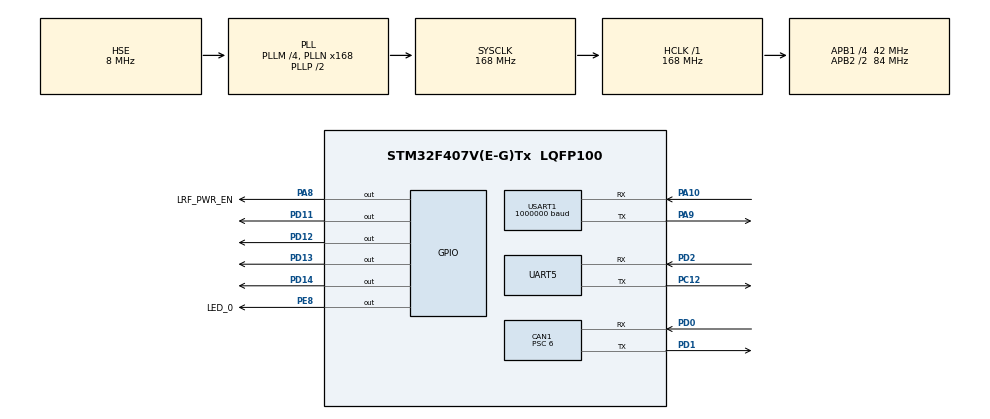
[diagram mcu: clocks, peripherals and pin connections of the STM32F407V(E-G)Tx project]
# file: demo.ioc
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CAN1.BS1=CAN_BS1_11TQ
CAN1.BS2=CAN_BS2_2TQ
CAN1.CalculateBaudRate=500000
CAN1.CalculateTimeBit=2000
CAN1.CalculateTimeQuantum=142.85714285714286
CAN1.Prescaler=6
Dma.Request0=UART5_RX
Dma.Request1=UART5_TX
Dma.Request2=USART1_RX
Dma.Request3=USART1_TX
Dma.UART5_RX.0.Direction=DMA_PERIPH_TO_MEMORY
Dma.UART5_RX.0.FIFOMode=DMA_FIFOMODE_DISABLE
Dma.UART5_RX.0.Instance=DMA1_Stream0
Dma.UART5_RX.0.MemDataAlignment=DMA_MDATAALIGN_BYTE
Dma.UART5_RX.0.MemInc=DMA_MINC_ENABLE
Dma.UART5_RX.0.Mode=DMA_NORMAL
Dma.UART5_RX.0.PeriphDataAlignment=DMA_PDATAALIGN_BYTE
Dma.UART5_RX.0.PeriphInc=DMA_PINC_DISABLE
Dma.UART5_RX.0.Priority=DMA_PRIORITY_LOW
Dma.UART5_TX.1.Direction=DMA_MEMORY_TO_PERIPH
Dma.UART5_TX.1.FIFOMode=DMA_FIFOMODE_DISABLE
Dma.UART5_TX.1.Instance=DMA1_Stream7
Dma.UART5_TX.1.MemDataAlignment=DMA_MDATAALIGN_BYTE
Dma.UART5_TX.1.MemInc=DMA_MINC_ENABLE
Dma.UART5_TX.1.Mode=DMA_NORMAL
Dma.UART5_TX.1.PeriphDataAlignment=DMA_PDATAALIGN_BYTE
Dma.UART5_TX.1.PeriphInc=DMA_PINC_DISABLE
Dma.UART5_TX.1.Priority=DMA_PRIORITY_LOW
Dma.USART1_RX.2.Direction=DMA_PERIPH_TO_MEMORY
Dma.USART1_RX.2.FIFOMode=DMA_FIFOMODE_DISABLE
Dma.USART1_RX.2.Instance=DMA2_Stream2
Dma.USART1_RX.2.MemDataAlignment=DMA_MDATAALIGN_BYTE
Dma.USART1_RX.2.MemInc=DMA_MINC_ENABLE
Dma.USART1_RX.2.Mode=DMA_NORMAL
Dma.USART1_RX.2.PeriphDataAlignment=DMA_PDATAALIGN_BYTE
Dma.USART1_RX.2.PeriphInc=DMA_PINC_DISABLE
Dma.USART1_RX.2.Priority=DMA_PRIORITY_LOW
Dma.USART1_TX.3.Direction=DMA_MEMORY_TO_PERIPH
Dma.USART1_TX.3.FIFOMode=DMA_FIFOMODE_DISABLE
Dma.USART1_TX.3.Instance=DMA2_Stream7
Dma.USART1_TX.3.MemDataAlignment=DMA_MDATAALIGN_BYTE
Dma.USART1_TX.3.MemInc=DMA_MINC_ENABLE
Dma.USART1_TX.3.Mode=DMA_NORMAL
Dma.USART1_TX.3.PeriphDataAlignment=DMA_PDATAALIGN_BYTE
Dma.USART1_TX.3.PeriphInc=DMA_PINC_DISABLE
Dma.USART1_TX.3.Priority=DMA_PRIORITY_LOW
Mcu.Family=STM32F4
Mcu.Name=STM32F407V(E-G)Tx
Mcu.Package=LQFP100
NVIC.DMA1_Stream0_IRQn=true\:0\:0\:false\:false\:true\:false\:true\:true
NVIC.DMA1_Stream7_IRQn=true\:0\:0\:false\:false\:true\:false\:true\:true
NVIC.DMA2_Stream2_IRQn=true\:0\:0\:false\:false\:true\:false\:true\:true
NVIC.DMA2_Stream7_IRQn=true\:0\:0\:false\:false\:true\:false\:true\:true
NVIC.PriorityGroup=NVIC_PRIORITYGROUP_4
NVIC.UART5_IRQn=true\:0\:0\:false\:false\:true\:true\:true\:true
PA10.Mode=Asynchronous
PA10.Signal=USART1_RX
PA13.Mode=Serial_Wire
PA13.Signal=SYS_JTMS-SWDIO
PA14.Mode=Serial_Wire
PA14.Signal=SYS_JTCK-SWCLK
PA8.GPIO_Label=LRF_PWR_EN
PA8.GPIO_PuPd=GPIO_NOPULL
PA8.PinState=GPIO_PIN_SET
PA8.Signal=GPIO_Output
PA9.Mode=Asynchronous
PA9.Signal=USART1_TX
PC12.Mode=Asynchronous
PC12.Signal=UART5_TX
PC14-OSC32_IN.Mode=LSE-External-Oscillator
PC14-OSC32_IN.Signal=RCC_OSC32_IN
PC15-OSC32_OUT.Mode=LSE-External-Oscillator
PC15-OSC32_OUT.Signal=RCC_OSC32_OUT
PD0.Mode=CAN_Activate
PD0.Signal=CAN1_RX
PD1.Mode=CAN_Activate
PD1.Signal=CAN1_TX
PD11.GPIO_Speed=GPIO_SPEED_FREQ_VERY_HIGH
PD11.Signal=GPIO_Output
PD12.GPIO_Speed=GPIO_SPEED_FREQ_VERY_HIGH
PD12.Signal=GPIO_Output
PD13.GPIO_Speed=GPIO_SPEED_FREQ_VERY_HIGH
PD13.Signal=GPIO_Output
PD14.GPIO_Speed=GPIO_SPEED_FREQ_VERY_HIGH
PD14.Signal=GPIO_Output
PD2.Mode=Asynchronous
PD2.Signal=UART5_RX
PE8.GPIO_Label=LED_0
PE8.Signal=GPIO_Output
PH0-OSC_IN.Mode=HSE-External-Oscillator
PH0-OSC_IN.Signal=RCC_OSC_IN
PH1-OSC_OUT.Mode=HSE-External-Oscillator
PH1-OSC_OUT.Signal=RCC_OSC_OUT
ProjectManager.HeapSize=0x200
ProjectManager.StackSize=0x400
ProjectManager.TargetToolchain=Makefile
RCC.48MHZClocksFreq_Value=84000000
RCC.AHBFreq_Value=168000000
RCC.APB1CLKDivider=RCC_HCLK_DIV4
RCC.APB1Freq_Value=42000000
RCC.APB1TimFreq_Value=84000000
RCC.APB2CLKDivider=RCC_HCLK_DIV2
RCC.APB2Freq_Value=84000000
RCC.APB2TimFreq_Value=168000000
RCC.CortexFreq_Value=168000000
RCC.HCLKFreq_Value=168000000
RCC.HSE_VALUE=8000000
RCC.HSI_VALUE=16000000
RCC.PLLM=4
RCC.PLLN=168
RCC.PLLSourceVirtual=RCC_PLLSOURCE_HSE
RCC.SYSCLKFreq_VALUE=168000000
RCC.SYSCLKSource=RCC_SYSCLKSOURCE_PLLCLK
RCC.VCOOutputFreq_Value=336000000
UART5.VirtualMode=Asynchronous
USART1.BaudRate=1000000
USART1.VirtualMode=VM_ASYNC
board=custom

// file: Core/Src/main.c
/* USER CODE BEGIN Header */
/**
  ******************************************************************************
  * @file           : main.c
  * @brief          : Main program body
  ******************************************************************************
  * @attention
  *
  * Copyright (c) 2025 STMicroelectronics.
  * All rights reserved.
  *
  * This software is licensed under terms that can be found in the LICENSE file
  * in the root directory of this software component.
  * If no LICENSE file comes with this software, it is provided AS-IS.
  *
  ******************************************************************************
  */
/* USER CODE END Header */
#include "main.h"

/* USER CODE BEGIN Includes */

#include "user_main.h"

/* USER CODE END Includes */

CAN_HandleTypeDef hcan1;

UART_HandleTypeDef huart5;
UART_HandleTypeDef huart1;
DMA_HandleTypeDef hdma_uart5_rx;
DMA_HandleTypeDef hdma_uart5_tx;
DMA_HandleTypeDef hdma_usart1_rx;
DMA_HandleTypeDef hdma_usart1_tx;

void SystemClock_Config(void);
static void MX_GPIO_Init(void);
static void MX_DMA_Init(void);
static void MX_CAN1_Init(void);
static void MX_UART5_Init(void);
static void MX_USART1_UART_Init(void);

int main(void)
{

  /* MCU Configuration--------------------------------------------------------*/

  /* Reset of all peripherals, Initializes the Flash interface and the Systick. */
  HAL_Init();

  /* Configure the system clock */
  SystemClock_Config();

  /* Initialize all configured peripherals */
  MX_GPIO_Init();
  MX_DMA_Init();
  MX_CAN1_Init();
  MX_UART5_Init();
  MX_USART1_UART_Init();
  /* USER CODE BEGIN 2 */

  user_init();
  /* USER CODE END 2 */

  /* Infinite loop */
  /* USER CODE BEGIN WHILE */
  while (1)
  {
    user_main();
    /* USER CODE END WHILE */

  }
}

void SystemClock_Config(void)
{
  RCC_OscInitTypeDef RCC_OscInitStruct = {0};
  RCC_ClkInitTypeDef RCC_ClkInitStruct = {0};

  /** Configure the main internal regulator output voltage
  */
  __HAL_RCC_PWR_CLK_ENABLE();
  __HAL_PWR_VOLTAGESCALING_CONFIG(PWR_REGULATOR_VOLTAGE_SCALE1);

  /** Initializes the RCC Oscillators according to the specified parameters
  * in the RCC_OscInitTypeDef structure.
  */
  RCC_OscInitStruct.OscillatorType = RCC_OSCILLATORTYPE_HSE;
  RCC_OscInitStruct.HSEState = RCC_HSE_ON;
  RCC_OscInitStruct.PLL.PLLState = RCC_PLL_ON;
  RCC_OscInitStruct.PLL.PLLSource = RCC_PLLSOURCE_HSE;
  RCC_OscInitStruct.PLL.PLLM = 4;
  RCC_OscInitStruct.PLL.PLLN = 168;
  RCC_OscInitStruct.PLL.PLLP = RCC_PLLP_DIV2;
  RCC_OscInitStruct.PLL.PLLQ = 4;
  if (HAL_RCC_OscConfig(&RCC_OscInitStruct) != HAL_OK)
  {
    Error_Handler();
  }

  /** Initializes the CPU, AHB and APB buses clocks
  */
  RCC_ClkInitStruct.ClockType = RCC_CLOCKTYPE_HCLK|RCC_CLOCKTYPE_SYSCLK
                              |RCC_CLOCKTYPE_PCLK1|RCC_CLOCKTYPE_PCLK2;
  RCC_ClkInitStruct.SYSCLKSource = RCC_SYSCLKSOURCE_PLLCLK;
  RCC_ClkInitStruct.AHBCLKDivider = RCC_SYSCLK_DIV1;
  RCC_ClkInitStruct.APB1CLKDivider = RCC_HCLK_DIV4;
  RCC_ClkInitStruct.APB2CLKDivider = RCC_HCLK_DIV2;

  if (HAL_RCC_ClockConfig(&RCC_ClkInitStruct, FLASH_LATENCY_5) != HAL_OK)
  {
    Error_Handler();
  }
}

static void MX_CAN1_Init(void)
{

  hcan1.Instance = CAN1;
  hcan1.Init.Prescaler = 6;
  hcan1.Init.Mode = CAN_MODE_NORMAL;
  hcan1.Init.SyncJumpWidth = CAN_SJW_1TQ;
  hcan1.Init.TimeSeg1 = CAN_BS1_11TQ;
  hcan1.Init.TimeSeg2 = CAN_BS2_2TQ;
  hcan1.Init.TimeTriggeredMode = DISABLE;
  hcan1.Init.AutoBusOff = DISABLE;
  hcan1.Init.AutoWakeUp = DISABLE;
  hcan1.Init.AutoRetransmission = DISABLE;
  hcan1.Init.ReceiveFifoLocked = DISABLE;
  hcan1.Init.TransmitFifoPriority = DISABLE;
  if (HAL_CAN_Init(&hcan1) != HAL_OK)
  {
    Error_Handler();
  }

}

static void MX_UART5_Init(void)
{

  huart5.Instance = UART5;
  huart5.Init.BaudRate = 115200;
  huart5.Init.WordLength = UART_WORDLENGTH_8B;
  huart5.Init.StopBits = UART_STOPBITS_1;
  huart5.Init.Parity = UART_PARITY_NONE;
  huart5.Init.Mode = UART_MODE_TX_RX;
  huart5.Init.HwFlowCtl = UART_HWCONTROL_NONE;
  huart5.Init.OverSampling = UART_OVERSAMPLING_16;
  if (HAL_UART_Init(&huart5) != HAL_OK)
  {
    Error_Handler();
  }

}

static void MX_USART1_UART_Init(void)
{

  huart1.Instance = USART1;
  huart1.Init.BaudRate = 1000000;
  huart1.Init.WordLength = UART_WORDLENGTH_8B;
  huart1.Init.StopBits = UART_STOPBITS_1;
  huart1.Init.Parity = UART_PARITY_NONE;
  huart1.Init.Mode = UART_MODE_TX_RX;
  huart1.Init.HwFlowCtl = UART_HWCONTROL_NONE;
  huart1.Init.OverSampling = UART_OVERSAMPLING_16;
  if (HAL_UART_Init(&huart1) != HAL_OK)
  {
    Error_Handler();
  }

}

static void MX_DMA_Init(void)
{

  /* DMA controller clock enable */
  __HAL_RCC_DMA1_CLK_ENABLE();
  __HAL_RCC_DMA2_CLK_ENABLE();

  /* DMA interrupt init */
  /* DMA1_Stream0_IRQn interrupt configuration */
  HAL_NVIC_SetPriority(DMA1_Stream0_IRQn, 0, 0);
  HAL_NVIC_EnableIRQ(DMA1_Stream0_IRQn);
  /* DMA1_Stream7_IRQn interrupt configuration */
  HAL_NVIC_SetPriority(DMA1_Stream7_IRQn, 0, 0);
  HAL_NVIC_EnableIRQ(DMA1_Stream7_IRQn);
  /* DMA2_Stream2_IRQn interrupt configuration */
  HAL_NVIC_SetPriority(DMA2_Stream2_IRQn, 0, 0);
  HAL_NVIC_EnableIRQ(DMA2_Stream2_IRQn);
  /* DMA2_Stream7_IRQn interrupt configuration */
  HAL_NVIC_SetPriority(DMA2_Stream7_IRQn, 0, 0);
  HAL_NVIC_EnableIRQ(DMA2_Stream7_IRQn);

}

static void MX_GPIO_Init(void)
{
  GPIO_InitTypeDef GPIO_InitStruct = {0};

  /* GPIO Ports Clock Enable */
  __HAL_RCC_GPIOC_CLK_ENABLE();
  __HAL_RCC_GPIOH_CLK_ENABLE();
  __HAL_RCC_GPIOE_CLK_ENABLE();
  __HAL_RCC_GPIOD_CLK_ENABLE();
  __HAL_RCC_GPIOA_CLK_ENABLE();

  /*Configure GPIO pin Output Level */
  HAL_GPIO_WritePin(LED_0_GPIO_Port, LED_0_Pin, GPIO_PIN_RESET);

  /*Configure GPIO pin Output Level */
  HAL_GPIO_WritePin(GPIOD, GPIO_PIN_11|GPIO_PIN_12|GPIO_PIN_13|GPIO_PIN_14, GPIO_PIN_RESET);

  /*Configure GPIO pin Output Level */
  HAL_GPIO_WritePin(LRF_PWR_EN_GPIO_Port, LRF_PWR_EN_Pin, GPIO_PIN_SET);

  /*Configure GPIO pin : LED_0_Pin */
  GPIO_InitStruct.Pin = LED_0_Pin;
  GPIO_InitStruct.Mode = GPIO_MODE_OUTPUT_PP;
  GPIO_InitStruct.Pull = GPIO_NOPULL;
  GPIO_InitStruct.Speed = GPIO_SPEED_FREQ_LOW;
  HAL_GPIO_Init(LED_0_GPIO_Port, &GPIO_InitStruct);

  /*Configure GPIO pins : PD11 PD12 PD13 PD14 */
  GPIO_InitStruct.Pin = GPIO_PIN_11|GPIO_PIN_12|GPIO_PIN_13|GPIO_PIN_14;
  GPIO_InitStruct.Mode = GPIO_MODE_OUTPUT_PP;
  GPIO_InitStruct.Pull = GPIO_NOPULL;
  GPIO_InitStruct.Speed = GPIO_SPEED_FREQ_VERY_HIGH;
  HAL_GPIO_Init(GPIOD, &GPIO_InitStruct);

  /*Configure GPIO pin : LRF_PWR_EN_Pin */
  GPIO_InitStruct.Pin = LRF_PWR_EN_Pin;
  GPIO_InitStruct.Mode = GPIO_MODE_OUTPUT_PP;
  GPIO_InitStruct.Pull = GPIO_NOPULL;
  GPIO_InitStruct.Speed = GPIO_SPEED_FREQ_LOW;
  HAL_GPIO_Init(LRF_PWR_EN_GPIO_Port, &GPIO_InitStruct);

}

void Error_Handler(void)
{
  __disable_irq();
  while (1)
  {
  }
}
